# STM32F303RDT6 register map
File version: 1.0
Registers are 32-bit, access not given, reset 0x0 unless marked. A register's access mark holds for its fields unless they carry their own. Offsets are from the block's base; [hi:lo] are bit positions; {n}, {i} and the like mark numbered series; 'fields as' and 'values as' point back to an identical list.

## TIM15
Base 0x40014000
0x00 CR1
  [11] UIFREMAP, [9:8] CKD, [7] ARPE, [31:4] s, [3] OPM, [2] URS, [1] UDIS, [0] CEN
0x04 CR2
  [10] OIS2, [9] OIS1N, [8] OIS1, [7] TI1S, [6:4] MMS, [3] CCDS, [2] CCUS, [31:1] s, [0] CCPC
0x08 SMCR
  [7] MSM, [6:4] TS, [31:3] s, [16:0] SMS
0x0C DIER
  [14] TDE, [13] COMDE, [10] CC2DE, [9] CC1DE, [8] UDE, [7] BIE, [6] TIE, [5] COMIE, [31:3] s, [2] CC2IE, [1] CC1IE, [0] UIE
0x10 SR
  [10] CC2OF, [9] CC1OF, [7] BIF, [6] TIF, [5] COMIF, [31:3] s, [2] CC2IF, [1] CC1IF, [0] UIF
0x14 EGR
  [7] BG, [6] TG, [5] COMG, [31:3] s, [2] CC2G, [1] CC1G, [0] UG
0x18 CCMR1_OUT
  [31:15] s, [24:12] OC2M, [11] OC2PE, [10] OC2FE, [9:8] CC2S, [7] OC1CE, [16:4] OC1M, [3] OC1PE, [2] OC1FE, [1:0] CC1S
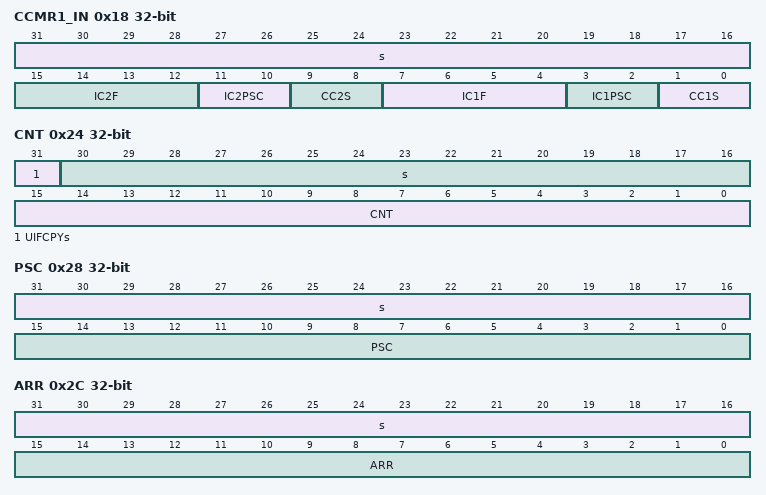
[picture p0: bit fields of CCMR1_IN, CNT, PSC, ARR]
0x18 CCMR1_IN
  [31:16] s, [15:12] IC2F, [11:10] IC2PSC, [9:8] CC2S, [7:4] IC1F, [3:2] IC1PSC, [1:0] CC1S
0x20 CCER
  [7] CC2NP, [31:6] s, [5] CC2P, [4] CC2E, [3] CC1NP, [2] CC1NE, [1] CC1P, [0] CC1E
0x24 CNT
  [31] UIFCPYs, [30:16] s, [15:0] CNT
0x28 PSC
  [31:16] s, [15:0] PSC
0x2C ARR
  [31:16] s, [15:0] ARR
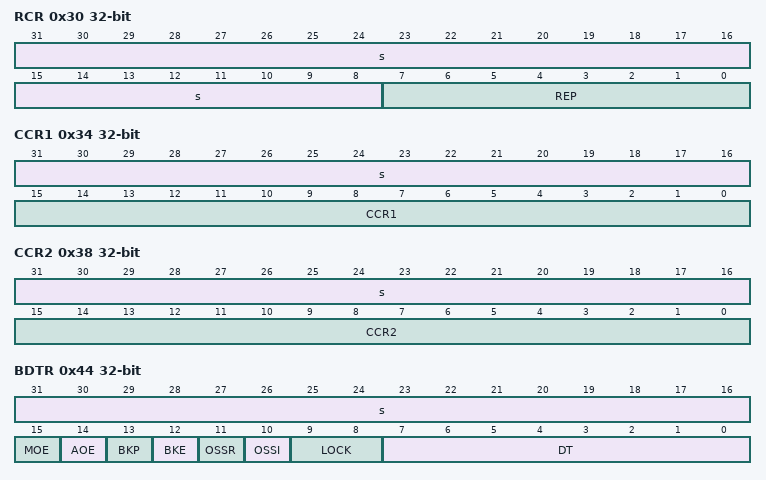
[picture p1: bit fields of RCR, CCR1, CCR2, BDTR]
0x30 RCR
  [31:8] s, [7:0] REP
0x34 CCR1
  [31:16] s, [15:0] CCR1
0x38 CCR2
  [31:16] s, [15:0] CCR2
0x44 BDTR
  [31:16] s, [15] MOE, [14] AOE, [13] BKP, [12] BKE, [11] OSSR, [10] OSSI, [9:8] LOCK, [7:0] DT
0x48 DCR
  [12:8] DBL, [31:5] s, [4:0] DBA
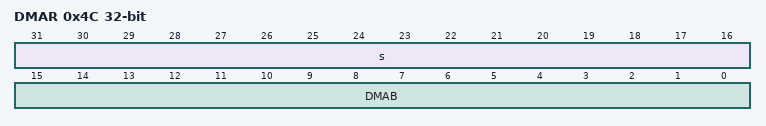
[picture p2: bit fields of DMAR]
0x4C DMAR
  [31:16] s, [15:0] DMAB

## TIM16
Base 0x40014400
0x00 CR1
  [11] UIFREMAP, [9:8] CKD, [7] ARPE, [31:4] s, [3] OPM, [2] URS, [1] UDIS, [0] CEN
0x04 CR2
  [9] OIS1N, [8] OIS1, [3] CCDS, [2] CCUS, [31:1] s, [0] CCPC
0x0C DIER
  [13] COMDE, [9] CC1DE, [8] UDE, [7] BIE, [5] COMIE, [31:2] s, [1] CC1IE, [0] UIE
0x10 SR
  [9] CC1OF, [7] BIF, [5] COMIF, [31:2] s, [1] CC1IF, [0] UIF
0x14 EGR
  [7] BG, [5] COMG, [31:2] s, [1] CC1G, [0] UG
0x18 CCMR1_OUT
  [31:8] s, [7] OC1CE, [16:4] OC1M, [3] OC1PE, [2] OC1FE, [1:0] CC1S
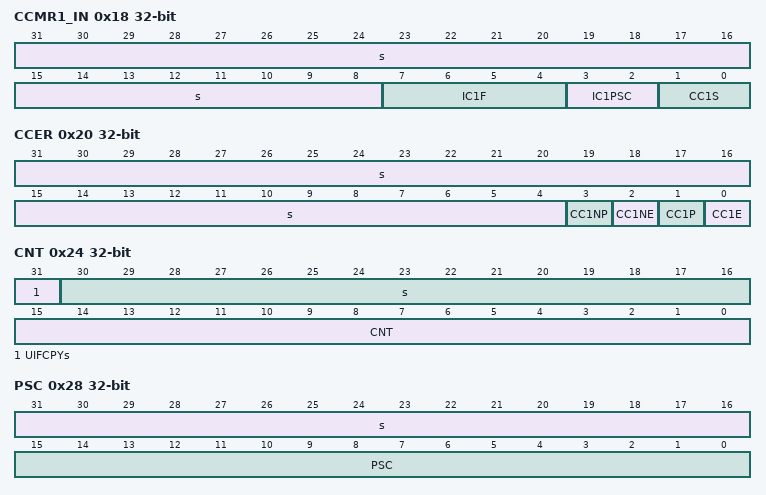
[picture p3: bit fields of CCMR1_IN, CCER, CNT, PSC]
0x18 CCMR1_IN
  [31:8] s, [7:4] IC1F, [3:2] IC1PSC, [1:0] CC1S
0x20 CCER
  [31:4] s, [3] CC1NP, [2] CC1NE, [1] CC1P, [0] CC1E
0x24 CNT
  [31] UIFCPYs, [30:16] s, [15:0] CNT
0x28 PSC
  [31:16] s, [15:0] PSC
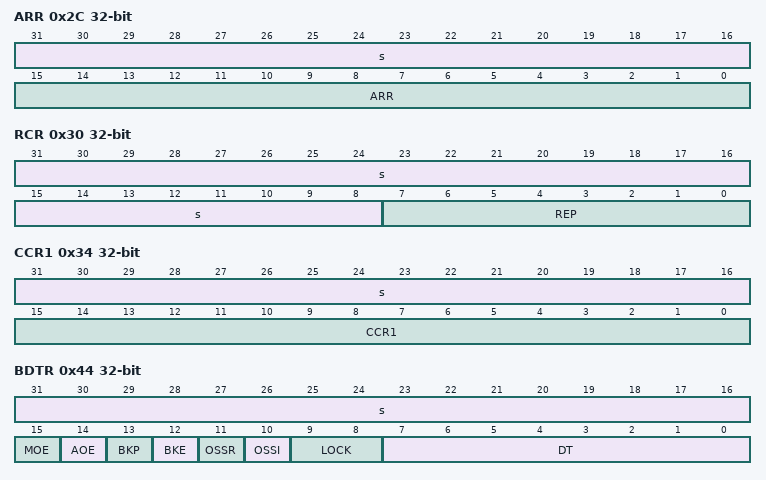
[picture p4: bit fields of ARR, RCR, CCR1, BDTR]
0x2C ARR
  [31:16] s, [15:0] ARR
0x30 RCR
  [31:8] s, [7:0] REP
0x34 CCR1
  [31:16] s, [15:0] CCR1
0x44 BDTR
  [31:16] s, [15] MOE, [14] AOE, [13] BKP, [12] BKE, [11] OSSR, [10] OSSI, [9:8] LOCK, [7:0] DT
0x48 DCR
  [12:8] DBL, [31:5] s, [4:0] DBA
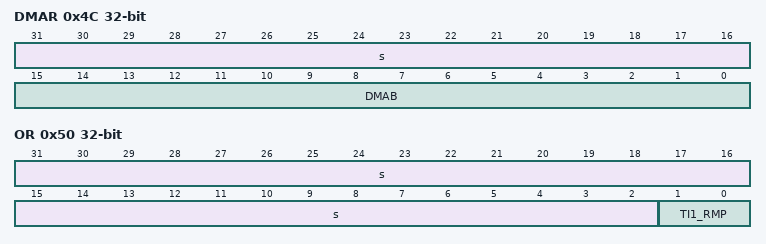
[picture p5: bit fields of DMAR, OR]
0x4C DMAR
  [31:16] s, [15:0] DMAB
0x50 OR
  [31:2] s, [1:0] TI1_RMP

## TIM17
Base 0x40014800
Registers as TIM16, without OR.

## DMA1
Base 0x40020000
Same registers: DMA2 0x40020400
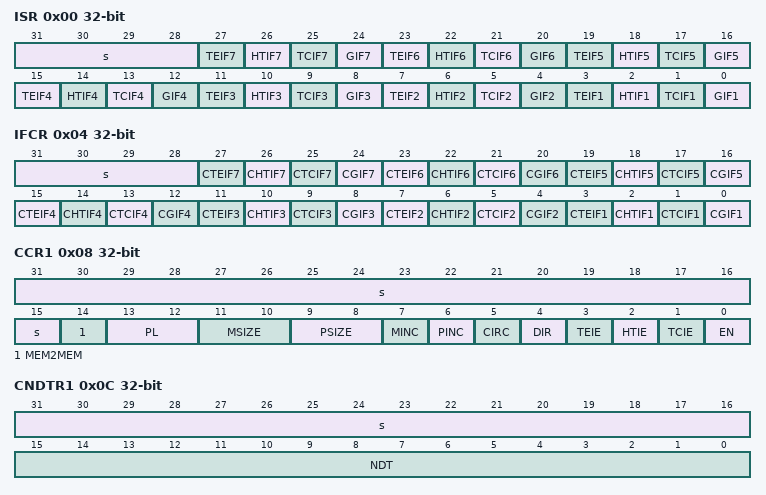
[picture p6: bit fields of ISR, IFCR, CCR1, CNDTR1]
0x00 ISR
  [31:28] s, [4n-1] TEIF{n} (n=1..7), [4n-2] HTIF{n} (n=1..7), [4n-3] TCIF{n} (n=1..7), [4n-4] GIF{n} (n=1..7)
0x04 IFCR
  [31:28] s, [4n-1] CTEIF{n} (n=1..7), [4n-2] CHTIF{n} (n=1..7), [4n-3] CTCIF{n} (n=1..7), [4n-4] CGIF{n} (n=1..7)
0x08 CCR1
  [31:15] s, [14] MEM2MEM, [13:12] PL, [11:10] MSIZE, [9:8] PSIZE, [7] MINC, [6] PINC, [5] CIRC, [4] DIR, [3] TEIE, [2] HTIE, [1] TCIE, [0] EN
0x0C CNDTR1
  [31:16] s, [15:0] NDT
0x10 CPAR1
  [31:0] PA
{0x0+0x14*i} CMAR{i} (i=1..7)
  [31:0] MA
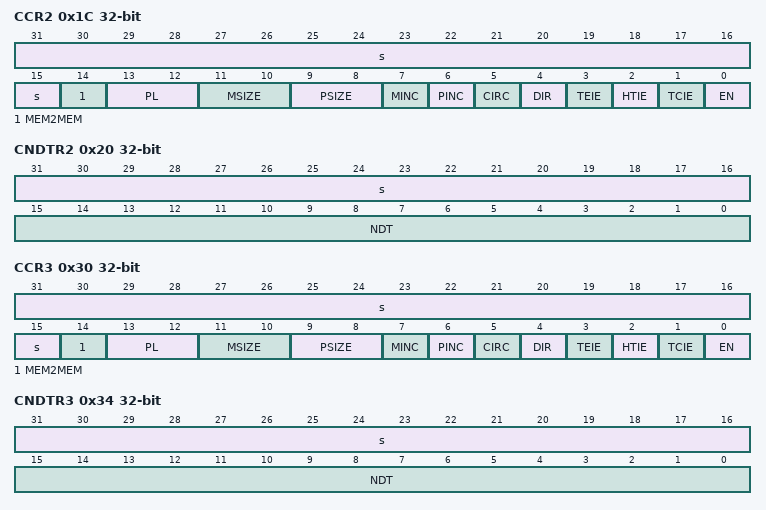
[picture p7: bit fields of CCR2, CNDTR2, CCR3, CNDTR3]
0x1C CCR2
  fields as CCR1
0x20 CNDTR2
  [31:16] s, [15:0] NDT
0x24 CPAR2
  [31:0] PA
0x30 CCR3
  fields as CCR1
0x34 CNDTR3
  [31:16] s, [15:0] NDT
0x38 CPAR3
  [31:0] PA
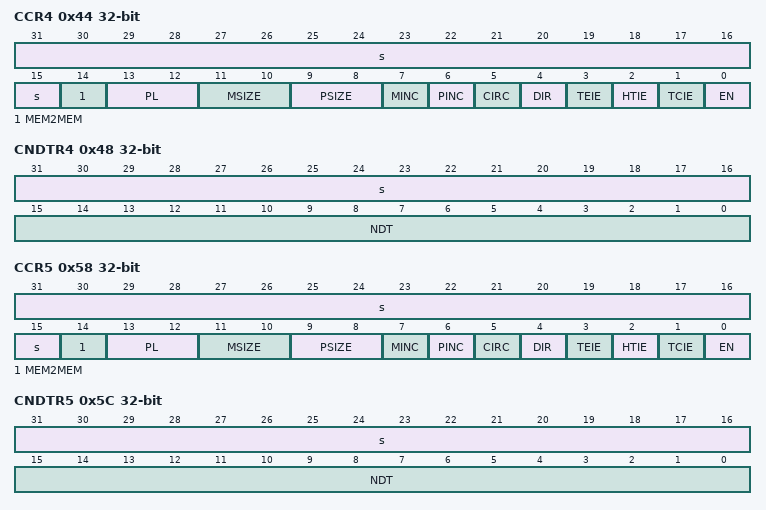
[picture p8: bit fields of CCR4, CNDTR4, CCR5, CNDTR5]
0x44 CCR4
  fields as CCR1
0x48 CNDTR4
  [31:16] s, [15:0] NDT
0x4C CPAR4
  [31:0] PA
0x58 CCR5
  fields as CCR1
0x5C CNDTR5
  [31:16] s, [15:0] NDT
0x60 CPAR5
  [31:0] PA
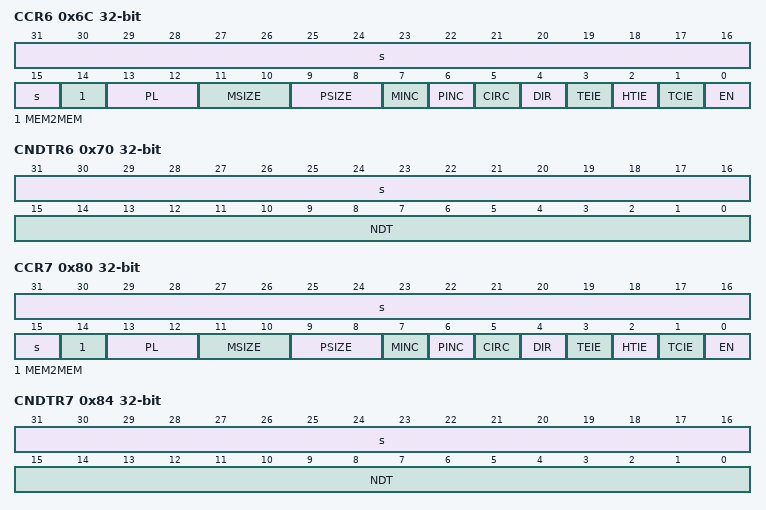
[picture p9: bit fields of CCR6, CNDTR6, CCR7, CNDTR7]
0x6C CCR6
  fields as CCR1
0x70 CNDTR6
  [31:16] s, [15:0] NDT
0x74 CPAR6
  [31:0] PA
0x80 CCR7
  fields as CCR1
0x84 CNDTR7
  [31:16] s, [15:0] NDT
0x88 CPAR7
  [31:0] PA

## RCC
Base 0x40021000
0x00 CR
  [25] PLLRDY, [24] PLLON, [19] CSSON, [18] HSEBYP, [17] HSERDY, [16] HSEON, [15:8] HSICAL, [7:3] HSITRIM, [31:2] s, [1] HSIRDY, [0] HSION
0x04 CFGR
  [31] PLLNODIV, [30:29] MCOPRE, [28] MCOPRE0/MCOF, [26:24] MCO, [23] I2SSRC, [22] USBPRE, [21:18] PLLMUL, [17] PLLXTPRE, [16:15] PLLSRC, [27:14] s, [13:11] PPRE2, [10:8] PPRE1, [7:4] HPRE, [3:2] SWS, [1:0] SW
0x08 CIR
  [23] CSSC, [20] PLLRDYC, [19] HSERDYC, [18] HSIRDYC, [17] LSERDYC, [16] LSIRDYC, [12] PLLRDYIE, [11] HSERDYIE, [10] HSIRDYIE, [9] LSERDYIE, [8] LSIRDYIE, [7] CSSF, [31:5] s, [4] PLLRDYF, [3] HSERDYF, [2] HSIRDYF, [1] LSERDYF, [0] LSIRDYF
0x0C APB2RSTR
  [17] TIM16RST, [16] TIM15RST, [15] SPI4RST, [14] USART1RST, [13] TIM8RST, [12] SPI1RST, [11] TIM1RST, [31:1] s, [0] SYSCFGRST
0x10 APB1RSTR
  [30] I2C3RST, [29] DAC1RST, [28] PWRRST, [26] DAC2RST, [25] CANRST, [23] USBRST, [22] I2C2RST, [21] I2C1RST, [20] UART5RST, [19] UART4RST, [18] USART3RST, [17] USART2RST, [15] SPI3RST, [14] SPI2RST, [11] WWDGRST, [5] TIM7RST, [4] TIM6RST, [31:3] s, [2] TIM4RST, [1] TIM3RST, [0] TIM2RST
0x14 AHBENR
  [29] ADC34EN, [28] ADC12EN, [24] TSCEN, [23] sIOPGEN, [22] IOPFEN, [21] IOPEEN, [20] IOPDEN, [19] IOPCEN, [18] IOPBEN, [17] IOPAEN, [16] IOPHEN, [6] CRCEN, [5] FMCEN, [4] FLITFEN, [31:3] s, [2] SRAMEN, [1] DMA2EN, [0] DMA1EN
0x18 APB2ENR
  [20] sTIM20EN, [18] TIM17EN, [17] TIM16EN, [16] TIM15EN, [15] sSPI4EN, [14] USART1EN, [13] TIM8EN, [12] SPI1EN, [11] TIM1EN, [31:1] s, [0] SYSCFGEN
0x1C APB1ENR
  [30] I2C3EN, [29] DAC1EN, [28] PWREN, [26] DAC2EN, [25] CANEN, [23] USBEN, [22] I2C2EN, [21] I2C1EN, [20] UART5EN, [19] UART4EN, [18] USART3EN, [17] USART2EN, [15] SP3EN, [14] SPI2EN, [11] WWDGEN, [5] TIM7EN, [4] TIM6EN, [31:3] s, [2] TIM4EN, [1] TIM3EN, [0] TIM2EN
0x20 BDCR
  [16] BDRST, [15] RTCEN, [9:8] RTCSEL, [31:5] s, [4:3] LSEDRV, [2] LSEBYP, [1] LSERDY, [0] LSEON
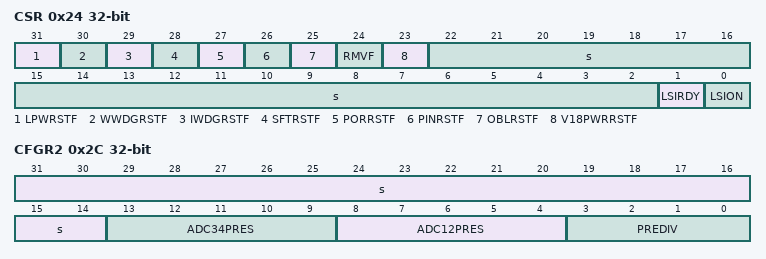
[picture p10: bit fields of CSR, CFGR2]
0x24 CSR
  [31] LPWRSTF, [30] WWDGRSTF, [29] IWDGRSTF, [28] SFTRSTF, [27] PORRSTF, [26] PINRSTF, [25] OBLRSTF, [24] RMVF, [23] V18PWRRSTF, [22:2] s, [1] LSIRDY, [0] LSION
0x28 AHBRSTR
  [29] ADC34RST, [28] ADC12RST, [24] TSCRST, [23] IOPGRST, [22] IOPFRST, [21] IOPERST, [20] IOPDRST, [19] IOPCRST, [18] IOPBRST, [17] IOPARST, [16] IOPHRST, [5] FMCRST, [31:0] s
0x2C CFGR2
  [31:14] s, [13:9] ADC34PRES, [8:4] ADC12PRES, [3:0] PREDIV
0x30 CFGR3
  [25] TIM34SW, [24] TIM2SW, [23:22] UART5SW, [21:20] UART4SW, [19:18] USART3SW, [17:16] USART2SW, [15] TIM20SW, [9] TIM8SW, [8] TIM1SW, [6] I2C3SW, [5] I2C2SW, [4] I2C1SW, [31:2] s, [1:0] USART1SW
